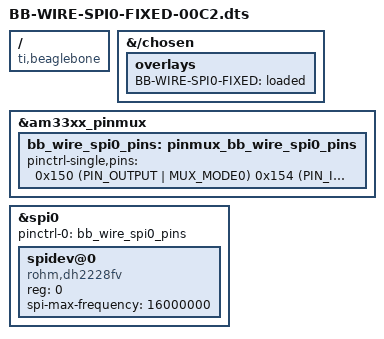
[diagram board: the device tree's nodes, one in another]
/dts-v1/;
/plugin/;
/include/ "dt-bindings/pinctrl/pinctrl-single.h"

/ {
	compatible = "ti,beaglebone", "ti,am33xx";

	/* Marker to see it at runtime */
	fragment@9 {
		target-path = "/chosen";
		__overlay__ {
			overlays { BB-WIRE-SPI0-FIXED = "loaded"; };
		};
	}

	/* --- SPI0 pinmux (P9_22=SCLK, P9_21=MISO, P9_18=MOSI, P9_17=CS0) --- */
	fragment@0 {
		target = <&am33xx_pinmux>;
		__overlay__ {
			bb_wire_spi0_pins: pinmux_bb_wire_spi0_pins {
				pinctrl-single,pins = <
					/* offset   flags                                   signal / header */
					0x150 (PIN_OUTPUT           | MUX_MODE0)    /* spi0_sclk   P9_22 */
					0x154 (PIN_INPUT_PULLUP     | MUX_MODE0)    /* spi0_d0     P9_21 (MISO) */
					0x158 (PIN_OUTPUT           | MUX_MODE0)    /* spi0_d1     P9_18 (MOSI) */
					0x15c (PIN_OUTPUT_PULLUP    | MUX_MODE0)    /* spi0_cs0    P9_17 */
				>;
			};
		};
	}

	/* --- Enable SPI0 and bind spidev on CS0 --- */
	fragment@1 {
		target = <&spi0>;
		__overlay__ {
			status = "okay";
			pinctrl-names = "default";
			pinctrl-0 = <&bb_wire_spi0_pins>;
			#address-cells = <1>;
			#size-cells    = <0>;

			spidev@0 {
				/* Use a real OF compatible that spidev matches in-tree */
				compatible = "rohm,dh2228fv";
				reg = <0>;                        /* CS0 */
				spi-max-frequency = <16000000>;
				status = "okay";
			};
		};
	}

	/* Export the pinmux label (handy for debug) */
	__symbols__ {
		bb_wire_spi0_pins = "/fragment@0/__overlay__/pinmux_bb_wire_spi0_pins";
	};
};

